# ATSAMG51G18 register map
Vendor: Atmel; Series: SAMG51; File version: 0
Atmel ATSAMG51G18 Microcontroller
CPU: CM4 r0p1, selectable endian, MPU, FPU, 4 interrupt priority bits
Registers are 32-bit, read-write, reset 0x0 unless marked. A register's access mark holds for its fields unless they carry their own. Offsets are from the block's base; lines under a group give offsets from that group; [hi:lo] are bit positions; {n}, {i} and the like mark numbered series; 'fields as' and 'values as' point back to an identical list; <NAME> marks a mode.

## Memory map
0x40008000 SPI size 0x4000 — Serial Peripheral Interface
0x40010000 TC0 size 0x4000 — Timer Counter 0
0x40018000 TWI0 size 0x4000 — Two-wire Interface High Speed
0x4001C000 TWI1 size 0x4000 — Two-wire Interface 1
0x40024000 USART size 0x4000 — Universal Synchronous Asynchronous Receiver Transmitter
0x40028000 MEM2MEM size 0x4000 — Memory to Memory
0x40038000 ADC size 0x4000 — Analog-to-Digital Converter
0x40040000 TWI2 size 0x4000 — Two-wire Interface 2
0x400E0200 MATRIX size 0x200 — AHB Bus Matrix
0x400E0400 PMC size 0x140 — Power Management Controller
0x400E0600 UART0 size 0x128 — Universal Asynchronous Receiver Transmitter 0
0x400E0740 CHIPID size 0x200 — Chip Identifier
0x400E0800 UART1 size 0x128 — Universal Asynchronous Receiver Transmitter 1
0x400E0A00 EFC size 0x200 — Embedded Flash Controller
0x400E0E00 PIOA size 0x200 — Parallel Input/Output Controller A
0x400E1000 PIOB size 0x200 — Parallel Input/Output Controller B
0x400E1400 RSTC size 0x200 — Reset Controller
0x400E1410 SUPC size 0x200 — Supply Controller
0x400E1430 RTT size 0x200 — Real-time Timer
0x400E1450 WDT size 0x200 — Watchdog Timer
0x400E1460 RTC size 0x200 — Real-time Clock
0x400E1490 GPBR size 0x200 — General Purpose Backup Registers

## Interrupts
5 PMC
6 EFC
8 UART0
9 UART1
11 PIOA
12 PIOB
14 USART
15 MEM2MEM
19 TWI0
20 TWI1
21 SPI
22 TWI2
23 TC0
24 TC1 (TC0)
25 TC2 (TC0)
29 ADC

## MEM2MEM — Memory to Memory
Base 0x40028000; register names take the prefix MEM2MEM_
0x00 THR — Memory to Memory Transfer Holding Register
  [31:0] THDATA — Transfer Holding Data
0x04 MR reset 0x2 — Memory to Memory Mode Register
  [1:0] TSIZE — Transfer Size
    0=T_8BIT (The buffer size is defined in byte.); 1=T_16BIT (The buffer size is defined in half-word (16-bit).); 2=T_32BIT (The buffer size is defined in word (32-bit). Default value.)
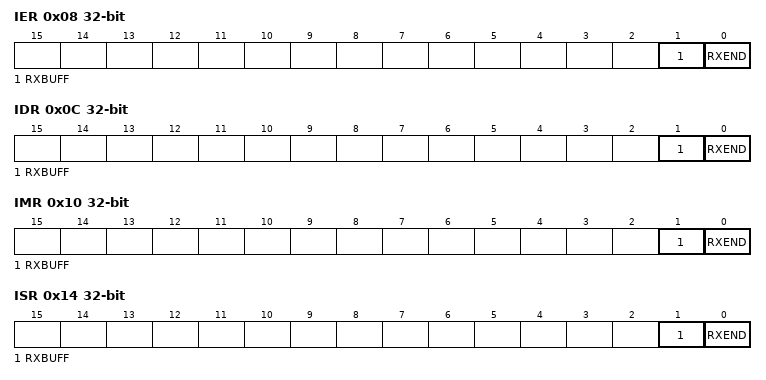
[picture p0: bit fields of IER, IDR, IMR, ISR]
0x08 IER wo reset not defined — Memory to Memory Interrupt Enable Register
  [1] RXBUFF — Buffer Full Interrupt Enable
  [0] RXEND — End of Transfer Interrupt Enable
0x0C IDR wo reset not defined — Memory to Memory Interrupt Disable Register
  [1] RXBUFF — Buffer Full Interrupt Disable
  [0] RXEND — End of Transfer Interrupt Disable
0x10 IMR ro — Memory to Memory Interrupt Mask Register
  [1] RXBUFF — Buffer Full Interrupt Mask
  [0] RXEND — End of Transfer Interrupt Mask
0x14 ISR ro reset not defined — Memory to Memory Interrupt Status Register
  [1] RXBUFF — Buffer Full
  [0] RXEND — End of Transfer
0x100 RPR — Receive Pointer Register
  [31:0] RXPTR
0x104 RCR — Receive Counter Register
  [15:0] RXCTR
0x108 TPR — Transmit Pointer Register
  [31:0] TXPTR — Transmit Counter Register
0x10C TCR — Transmit Counter Register
  [15:0] TXCTR
0x110 RNPR — Receive Next Pointer Register
  [31:0] RXNPTR — Receive Next Pointer
0x114 RNCR — Receive Next Counter Register
  [15:0] RXNCTR — Receive Next Counter
0x118 TNPR — Transmit Next Pointer Register
  [31:0] TXNPTR — Transmit Next Pointer
0x11C TNCR — Transmit Next Counter Register
  [15:0] TXNCTR — Transmit Counter Next
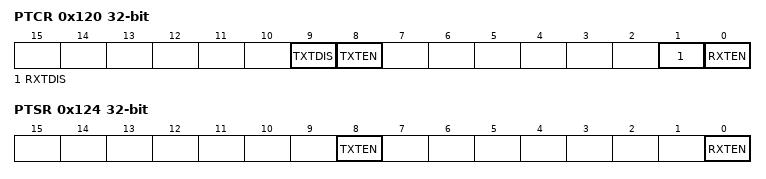
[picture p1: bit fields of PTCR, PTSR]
0x120 PTCR wo — Transfer Control Register
  [9] TXTDIS — Transmitter Transfer Disable
  [8] TXTEN — Transmitter Transfer Enable
  [1] RXTDIS — Receiver Transfer Disable
  [0] RXTEN — Receiver Transfer Enable
0x124 PTSR ro — Transfer Status Register
  [8] TXTEN — Transmitter Transfer Enable
  [0] RXTEN — Receiver Transfer Enable

## MATRIX — AHB Bus Matrix
Base 0x400E0200
{0x0+4i} MATRIX_MCFG[{i}] (i=0..2) reset not defined — Master Configuration Register
  [2:0] ULBT — Undefined Length Burst Type
    0=INFINITE (No predicted end of burst is generated and therefore INCR bursts coming from this master cannot be broken.); 1=SINGLE (The undefined length burst is treated as a succession of single access allowing rearbitration at each beat of the INCR burst.); 2=FOUR_BEAT (The undefined length burst is split into a 4-beat bursts allowing rearbitration at each 4-beat burst end.); 3=EIGHT_BEAT (The undefined length burst is split into 8-beat bursts allowing rearbitration at each 8-beat burst end.); 4=SIXTEEN_BEAT (The undefined length burst is split into 16-beat bursts allowing rearbitration at each 16-beat burst end.)
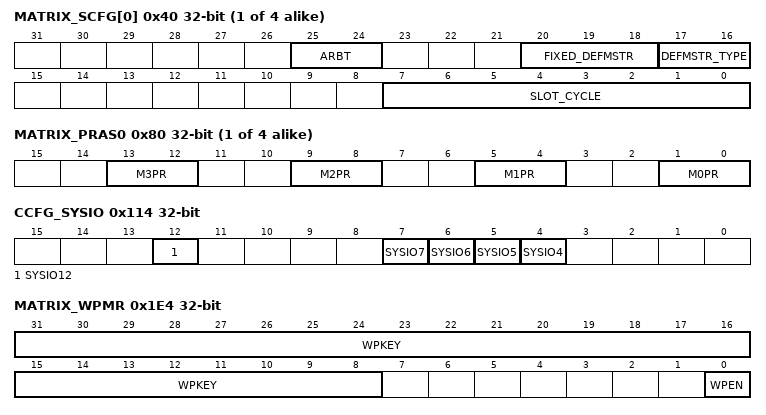
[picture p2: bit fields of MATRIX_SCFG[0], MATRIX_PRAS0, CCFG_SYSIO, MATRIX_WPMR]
{0x40+4i} MATRIX_SCFG[{i}] (i=0..3) reset not defined — Slave Configuration Register
  [25:24] ARBT — Arbitration Type
    0=ROUND_ROBIN (Round-robin arbitration); 1=FIXED_PRIORITY (Fixed priority arbitration)
  [20:18] FIXED_DEFMSTR — Fixed Default Master
  [17:16] DEFMSTR_TYPE — Default Master Type
    0=NO_DEFAULT (At the end of current slave access, if no other master request is pending, the slave is disconnected from all masters.This results in having a one cycle latency for the first access of a burst transfer or for a single access.); 1=LAST (At the end of current slave access, if no other master request is pending, the slave stays connected to the last master having accessed it.This results in not having the one cycle latency when the last master tries to access the slave again.); 2=FIXED (At the end of the current slave access, if no other master request is pending, the slave connects to the fixed master the number that has been written in the FIXED_DEFMSTR field.This results in not having the one cycle latency when the fixed master tries to access the slave again.)
  [7:0] SLOT_CYCLE — Maximum Number of Allowed Cycles for a Burst
{0x80+8i} MATRIX_PRAS{i} (i=0..3) — Priority Register A for Slave {i}
  [4n+1:4n] M{n}PR (n=0..3) — Master {n} Priority
0x114 CCFG_SYSIO — System I/O Configuration Register
  [12] SYSIO12 — PB12 or ERASE Assignment
  [7] SYSIO7 — PB7 or TCK/SWCLK Assignment
  [6] SYSIO6 — PB6 or TMS/SWDIO Assignment
  [5] SYSIO5 — PB5 or TDO/TRACESWO Assignment
  [4] SYSIO4 — PB4 or TDI Assignment
0x1E4 MATRIX_WPMR — Write Protection Mode Register
  [31:8] WPKEY — Write Protection Key
    0x4D4154=PASSWD (Writing any other value in this field aborts the write operation of the WPEN bit. Always reads as 0.)
  [0] WPEN — Write Protection Enable
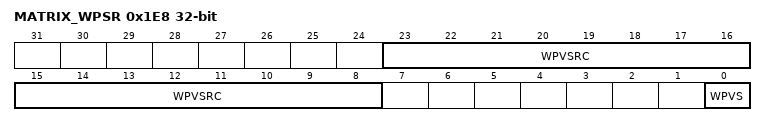
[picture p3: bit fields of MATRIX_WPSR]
0x1E8 MATRIX_WPSR ro — Write Protection Status Register
  [23:8] WPVSRC — Write Protection Violation Source
  [0] WPVS — Write Protection Violation Status

## Notices in the file
SAM Software Package License
Copyright (c) 2014, Atmel Corporation
All rights reserved.
Redistribution and use in source and binary forms, with or without
modification, are permitted provided that the following condition is met:
- Redistributions of source code must retain the above copyright notice,
this list of conditions and the disclaimer below.
Atmel's name may not be used to endorse or promote products derived from
this software without specific prior written permission.
DISCLAIMER:  THIS SOFTWARE IS PROVIDED BY ATMEL "AS IS" AND ANY EXPRESS OR
IMPLIED WARRANTIES, INCLUDING, BUT NOT LIMITED TO, THE IMPLIED WARRANTIES OF
MERCHANTABILITY, FITNESS FOR A PARTICULAR PURPOSE AND NON-INFRINGEMENT ARE
DISCLAIMED. IN NO EVENT SHALL ATMEL BE LIABLE FOR ANY DIRECT, INDIRECT,
INCIDENTAL, SPECIAL, EXEMPLARY, OR CONSEQUENTIAL DAMAGES (INCLUDING, BUT NOT
LIMITED TO, PROCUREMENT OF SUBSTITUTE GOODS OR SERVICES; LOSS OF USE, DATA,
OR PROFITS; OR BUSINESS INTERRUPTION) HOWEVER CAUSED AND ON ANY THEORY OF
LIABILITY, WHETHER IN CONTRACT, STRICT LIABILITY, OR TORT (INCLUDING
NEGLIGENCE OR OTHERWISE) ARISING IN ANY WAY OUT OF THE USE OF THIS SOFTWARE,
EVEN IF ADVISED OF THE POSSIBILITY OF SUCH DAMAGE.
